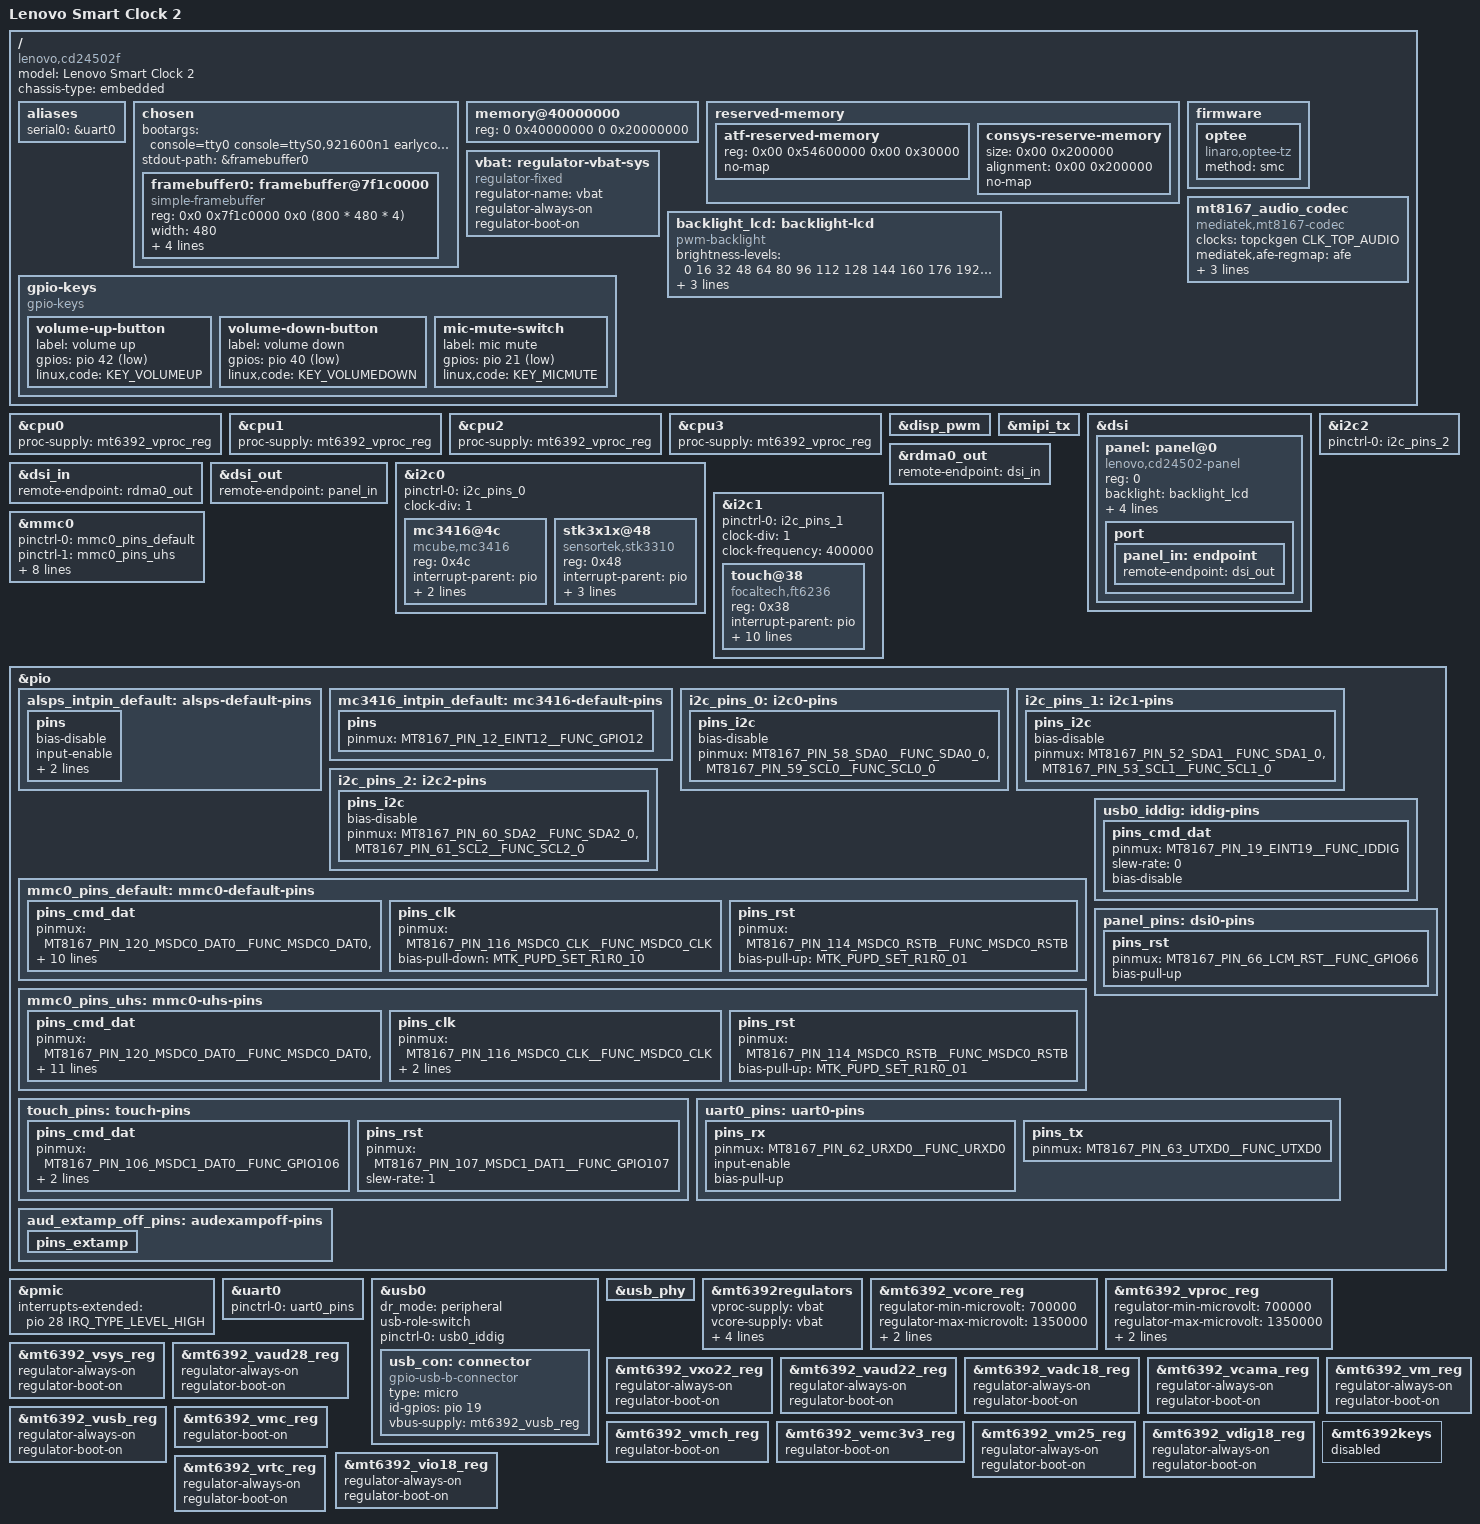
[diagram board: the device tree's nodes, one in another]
// SPDX-License-Identifier: GPL-2.0
/*
 * Copyright (c) 2025 FIXME
 */
/dts-v1/;
#include <dt-bindings/gpio/gpio.h>
#include <dt-bindings/input/linux-event-codes.h>
#include "mt8167.dtsi"
#include "mt6392.dtsi"

/ {
	model = "Lenovo Smart Clock 2";
	chassis-type = "embedded";
	compatible = "lenovo,cd24502f", "mediatek,mt8167";

	aliases {
		serial0 = &uart0;
	};

	chosen {
		#address-cells = <2>;
		#size-cells = <2>;
		bootargs = "console=tty0 console=ttyS0,921600n1 earlycon=uart8250,mmio32,0x11005000 fbcon=rotate:1";
		ranges;

		stdout-path = &framebuffer0;

		framebuffer0: framebuffer@7f1c0000 {
			compatible = "simple-framebuffer";
			reg = <0x0 0x7f1c0000 0x0 (800 * 480 * 4)>;
			width = <480>;
			height = <800>;
			stride = <(480 * 4)>;
			format = "a8r8g8b8";
			display = <&dsi>;
		};
	};

	memory@40000000 {
		device_type = "memory";
		reg = <0 0x40000000 0 0x20000000>;
	};

	reserved-memory {
		#address-cells = <2>;
		#size-cells = <2>;
		ranges;

		atf-reserved-memory {
			reg = <0x00 0x54600000 0x00 0x30000>;
			no-map;
		};

		consys-reserve-memory {
			size = <0x00 0x200000>;
			alignment = <0x00 0x200000>;
			no-map;
		};
	};

	firmware {
		optee {
			compatible = "linaro,optee-tz";
			method = "smc";
		};
	};

	vbat: regulator-vbat-sys {
		compatible = "regulator-fixed";
		regulator-name = "vbat";
		regulator-always-on;
		regulator-boot-on;
	};

	backlight_lcd: backlight-lcd {
		compatible = "pwm-backlight";
		brightness-levels = <
			  0  16  32  48  64  80  96 112
			128 144 160 176 192 208 224 240
			255
		>;
		default-brightness-level = <9>;
		power-supply = <&mt6392_vmch_reg>;
		pwms = <&disp_pwm 0 1000000>;
	};

	mt8167_audio_codec: mt8167_audio_codec {
		compatible = "mediatek,mt8167-codec";
		clocks = <&topckgen CLK_TOP_AUDIO>;
		clock-names = "bus";
		mediatek,afe-regmap = <&afe>;
		mediatek,apmixedsys-regmap = <&apmixedsys>;
		mediatek,dmic-wire-mode = <1>; /* 0(ONE_WIRE) 1(TWO_WIRE) */
		mediatek,headphone-cap-sel = <1>; /* 0(10UF) 1(22UF) 2(33UF) 3(47UF) */
	};
/*
	sound {
		compatible = "mediatek,mt8167s-es7243";
		mediatek,platform = <&afe>;
		pinctrl-0 = <&aud_default_pins>;
		pinctrl-1 = <&aud_extamp_on_pins>;
		pinctrl-2 = <&aud_extamp_off_pins>;
		pinctrl-names = "default", "extamp_on", "extamp_off";
		tdmadc-3p3v-supply = <&mt6392_vmch_reg>;
		tdmadc-1p8v-supply = <&mt6392_vcamio_reg>;
	};
*/
	gpio-keys {
		compatible = "gpio-keys";

		volume-up-button {
			label = "volume up";
			gpios = <&pio 42 GPIO_ACTIVE_LOW>;
			linux,code = <KEY_VOLUMEUP>;
		};

		volume-down-button {
			label = "volume down";
			gpios = <&pio 40 GPIO_ACTIVE_LOW>;
			linux,code = <KEY_VOLUMEDOWN>;
		};

		mic-mute-switch {
			label = "mic mute";
			gpios = <&pio 21 GPIO_ACTIVE_LOW>;
			linux,code = <KEY_MICMUTE>;
		};
	};
};

/* With the firmware on Android devices, cores don't seem to come back after out
   idle/unplug (though initial SMP boot is fine) */

&cpu0 {
	/delete-property/ cpu-idle-states;
	proc-supply = <&mt6392_vproc_reg>;
};

&cpu1 {
	/delete-property/ cpu-idle-states;
	proc-supply = <&mt6392_vproc_reg>;
};

&cpu2 {
	/delete-property/ cpu-idle-states;
	proc-supply = <&mt6392_vproc_reg>;
};

&cpu3 {
	/delete-property/ cpu-idle-states;
	proc-supply = <&mt6392_vproc_reg>;
};

/*
&cluster0_opp {
	opp-1500000000 {
		opp-hz = /bits/ 64 <1500000000>;
		opp-microvolt = <1300000>;
	};
};
*/
&disp_pwm {
	status = "okay";
};

&mipi_tx {
	status = "okay";
};

&dsi {
	status = "okay";

	panel: panel@0 {
		compatible = "lenovo,cd24502-panel";
		reg = <0>;
		backlight = <&backlight_lcd>;
		reset-gpios = <&pio 66 GPIO_ACTIVE_LOW>;
		rotation = <90>;
		power-supply = <&mt6392_vgp1_reg>;

		pinctrl-names = "default";
		pinctrl-0 = <&panel_pins>;

		port {
			panel_in: endpoint {
				remote-endpoint = <&dsi_out>;
			};
		};
	};
};

&rdma0_out {
	remote-endpoint = <&dsi_in>;
};

&dsi_in {
	remote-endpoint = <&rdma0_out>;
};

&dsi_out {
	remote-endpoint = <&panel_in>;
};

&i2c0 {
	pinctrl-names = "default";
	pinctrl-0 = <&i2c_pins_0>;
	clock-div = <1>;
	status = "okay";

	/* Accelerometer is mCube MC3416 */
	mc3416@4c {
		reg = <0x4c>;
		compatible = "mcube,mc3416";
		interrupt-parent = <&pio>;
		interrupts = <12 IRQ_TYPE_LEVEL_LOW>;
		pinctrl-names = "default";
		pinctrl-0 = <&mc3416_intpin_default>;
	};

	/* ALS/PS is Sensortek STK3310 */
	stk3x1x@48 {
		reg = <0x48>;
		compatible = "sensortek,stk3310";
		interrupt-parent = <&pio>;
		interrupts = <5 IRQ_TYPE_LEVEL_LOW>;
		proximity-near-level = <25>;
		pinctrl-names = "default";
		pinctrl-0 = <&alsps_intpin_default>;
	};
};

&i2c1 {
	pinctrl-names = "default";
	pinctrl-0 = <&i2c_pins_1>;
	status = "okay";
	clock-div = <1>;
	clock-frequency = <400000>;

	/* Touch is "EP0110M09" (FocalTech FT6336U?) */
	touch@38 {
		reg = <0x38>;
		compatible = "focaltech,ft6236";
		interrupt-parent = <&pio>;
		interrupts = <106 IRQ_TYPE_EDGE_FALLING>;
		reset-gpios = <&pio 107 GPIO_ACTIVE_LOW>;

		vcc-supply = <&mt6392_vio28_reg>;
		iovcc-supply = <&mt6392_vgp1_reg>;

		panel = <&panel>;
		touchscreen-size-x = <480>;
		touchscreen-size-y = <800>;
		//touchscreen-inverted-y;
		touchscreen-swapped-x-y;

		wakeup-source;

		pinctrl-names = "default";
		pinctrl-0 = <&touch_pins>;
	};
};

&i2c2 {
	pinctrl-names = "default";
	pinctrl-0 = <&i2c_pins_2>;
	status = "okay";
/*
	tas5805m: tas5805m@2d {
		compatible = "ti,tas5805m";
		pinctrl-names = "default";
		pinctrl-0 = <&spk_pin_default>;
		reg = <0x2d>;
		power_gpio = <&pio 69 0>;
		fault_gpio = <&pio 70 0>;
	};

	ad82128: ad82128@31 {
		compatible = "ESMT,ad82128";
		pinctrl-names = "default";
		pinctrl-0 = <&spk_pin_default>;
		reg = <0x31>;
		power_gpio = <&pio 69 0>;
		fault_gpio = <&pio 70 0>;
	};
		
	clock2@1d {
		reg = <0x1d>;
		compatible = "Tonly,clock2";

		interrupt-parent = <&pio>;
		interrupts = <18 IRQ_TYPE_EDGE_FALLING>;

	};*/
};

&mmc0 {
	status = "okay";

	pinctrl-names = "default", "state_uhs";
	pinctrl-0 = <&mmc0_pins_default>;
	pinctrl-1 = <&mmc0_pins_uhs>;

	bus-width = <8>;
	max-frequency = <200000000>;
	cap-mmc-highspeed;
	mmc-hs200-1_8v;
	cap-mmc-hw-reset;
	non-removable;

	vmmc-supply = <&mt6392_vemc3v3_reg>;
	vqmmc-supply = <&mt6392_vio18_reg>;
};

&pio {
	alsps_intpin_default: alsps-default-pins {
		pins {
			bias-disable;
			input-enable;
			slew-rate = <0>;
			pinmux = <MT8167_PIN_5_EINT5__FUNC_GPIO5>;
		};
	};

	mc3416_intpin_default: mc3416-default-pins {
		pins {
			pinmux = <MT8167_PIN_12_EINT12__FUNC_GPIO12>;
		};
	};

	i2c_pins_0: i2c0-pins {
		pins_i2c {
			bias-disable;
			pinmux = <MT8167_PIN_58_SDA0__FUNC_SDA0_0>,
				 <MT8167_PIN_59_SCL0__FUNC_SCL0_0>;
		};
	};

	i2c_pins_1: i2c1-pins {
		pins_i2c {
			bias-disable;
			pinmux = <MT8167_PIN_52_SDA1__FUNC_SDA1_0>,
				 <MT8167_PIN_53_SCL1__FUNC_SCL1_0>;
		};
	};

	i2c_pins_2: i2c2-pins {
		pins_i2c {
			bias-disable;
			pinmux = <MT8167_PIN_60_SDA2__FUNC_SDA2_0>,
				 <MT8167_PIN_61_SCL2__FUNC_SCL2_0>;
		};
	};
	
	mmc0_pins_default: mmc0-default-pins {
		pins_cmd_dat {
			pinmux = <MT8167_PIN_120_MSDC0_DAT0__FUNC_MSDC0_DAT0>,
				 <MT8167_PIN_119_MSDC0_DAT1__FUNC_MSDC0_DAT1>,
				 <MT8167_PIN_118_MSDC0_DAT2__FUNC_MSDC0_DAT2>,
				 <MT8167_PIN_117_MSDC0_DAT3__FUNC_MSDC0_DAT3>,
				 <MT8167_PIN_113_MSDC0_DAT4__FUNC_MSDC0_DAT4>,
				 <MT8167_PIN_112_MSDC0_DAT5__FUNC_MSDC0_DAT5>,
				 <MT8167_PIN_111_MSDC0_DAT6__FUNC_MSDC0_DAT6>,
				 <MT8167_PIN_110_MSDC0_DAT7__FUNC_MSDC0_DAT7>,
				 <MT8167_PIN_115_MSDC0_CMD__FUNC_MSDC0_CMD>;
			input-enable;
			bias-pull-up = <MTK_PUPD_SET_R1R0_01>;
		};

		pins_clk {
			pinmux = <MT8167_PIN_116_MSDC0_CLK__FUNC_MSDC0_CLK>;
			bias-pull-down = <MTK_PUPD_SET_R1R0_10>;
		};

		pins_rst {
			pinmux = <MT8167_PIN_114_MSDC0_RSTB__FUNC_MSDC0_RSTB>;
			bias-pull-up = <MTK_PUPD_SET_R1R0_01>;
		};
	};

	mmc0_pins_uhs: mmc0-uhs-pins {
		pins_cmd_dat {
			pinmux = <MT8167_PIN_120_MSDC0_DAT0__FUNC_MSDC0_DAT0>,
				 <MT8167_PIN_119_MSDC0_DAT1__FUNC_MSDC0_DAT1>,
				 <MT8167_PIN_118_MSDC0_DAT2__FUNC_MSDC0_DAT2>,
				 <MT8167_PIN_117_MSDC0_DAT3__FUNC_MSDC0_DAT3>,
				 <MT8167_PIN_113_MSDC0_DAT4__FUNC_MSDC0_DAT4>,
				 <MT8167_PIN_112_MSDC0_DAT5__FUNC_MSDC0_DAT5>,
				 <MT8167_PIN_111_MSDC0_DAT6__FUNC_MSDC0_DAT6>,
				 <MT8167_PIN_110_MSDC0_DAT7__FUNC_MSDC0_DAT7>,
				 <MT8167_PIN_115_MSDC0_CMD__FUNC_MSDC0_CMD>;
			input-enable;
			drive-strength = <MTK_DRIVE_6mA>;
			bias-pull-up = <MTK_PUPD_SET_R1R0_01>;
		};

		pins_clk {
			pinmux = <MT8167_PIN_116_MSDC0_CLK__FUNC_MSDC0_CLK>;
			drive-strength = <MTK_DRIVE_8mA>;
			bias-pull-down = <MTK_PUPD_SET_R1R0_10>;
		};

		pins_rst {
			pinmux = <MT8167_PIN_114_MSDC0_RSTB__FUNC_MSDC0_RSTB>;
			bias-pull-up = <MTK_PUPD_SET_R1R0_01>;
		};
	};
/*
	drvvbus_default: drvvbus-default-pins {
		pins_cmd_dat {
			pinmux = <MT8167_PIN_6_EINT6__FUNC_GPIO6>;
			output-low;
		};
	};

	usb_switch_default: usb-switch-pins {
		pins_cmd_dat {
			pinmux = <MT8167_PIN_12_EINT12__FUNC_PWM_A>;
			output-low;
		};
	};
*/
	usb0_iddig: iddig-pins {
		pins_cmd_dat {
			pinmux = <MT8167_PIN_19_EINT19__FUNC_IDDIG>;
			slew-rate = <0>;
			bias-disable;
		};
	};

	panel_pins: dsi0-pins {
		pins_rst {
			pinmux = <MT8167_PIN_66_LCM_RST__FUNC_GPIO66>;
			bias-pull-up;
		};
	};

	touch_pins: touch-pins {
		pins_cmd_dat {
			pinmux = <MT8167_PIN_106_MSDC1_DAT0__FUNC_GPIO106>;
			input-enable;
			bias-disable;
		};

		pins_rst {
			pinmux = <MT8167_PIN_107_MSDC1_DAT1__FUNC_GPIO107>;
			slew-rate = <1>;
		};
	};

	uart0_pins: uart0-pins {
		pins_rx {
			pinmux = <MT8167_PIN_62_URXD0__FUNC_URXD0>;
			input-enable;
			bias-pull-up;
		};
		pins_tx {
			pinmux = <MT8167_PIN_63_UTXD0__FUNC_UTXD0>;
		};
	};

	aud_extamp_off_pins: audexampoff-pins {
		pins_extamp {
			/*output-low;
			slew-rate = <1>;
			pinmux = <MT8167_PIN_51_SPI_MO__FUNC_GPIO51>;*/
		};
	};
/*
	aud_extamp_on_pins: audexampon-pins {
		pins_extamp {
			output-high;
			slew-rate = <1>;
			pinmux = <MT8167_PIN_51_SPI_MO__FUNC_GPIO51>;
		};
	};

	aud_default_pins: audiodefault-pins {
		pins_extamp {
			output-low;
			slew-rate = <1>;
			pinmux = <MT8167_PIN_51_SPI_MO__FUNC_GPIO51>;
		};

		pins_cmd_dat {
			drive-strength = <MTK_DRIVE_4mA>;
			pinmux = <MT8167_PIN_71_MSDC2_DAT1__FUNC_I2S_8CH_DO1
				  MT8167_PIN_72_MSDC2_DAT2__FUNC_I2S_8CH_LRCK
				  MT8167_PIN_73_MSDC2_DAT3__FUNC_I2S_8CH_BCK
				  MT8167_PIN_38_MRG_DI__FUNC_I2S0_DI>;
		};
	};*/
};

&pmic {
	interrupts-extended = <&pio 28 IRQ_TYPE_LEVEL_HIGH>;
};

&uart0 {
	status = "okay";

	pinctrl-names = "default";
	pinctrl-0 = <&uart0_pins>;
};

&usb0 {
	status = "okay";
	dr_mode = "peripheral";
	usb-role-switch;

	pinctrl-names = "default";
	pinctrl-0 = <&usb0_iddig>;

	//vusb33-supply = <&mt6392_vusb_reg>;

	usb_con: connector {
		compatible = "gpio-usb-b-connector", "usb-b-connector";
		type = "micro";
		id-gpios = <&pio 19 GPIO_OPEN_SOURCE>;
		vbus-supply = <&mt6392_vusb_reg>;
	};
};

&usb_phy {
	status = "okay";
};

&mt6392regulators {
	vproc-supply = <&vbat>;
	vcore-supply = <&vbat>;
	vsys-supply = <&vbat>;
	ldo1-supply = <&vbat>;
	ldo2-supply = <&vbat>;
	ldo3-supply = <&vbat>;
};

&mt6392_vcore_reg {
	regulator-min-microvolt = <700000>;
	regulator-max-microvolt = <1350000>;
	regulator-always-on;
	regulator-boot-on;
};

&mt6392_vproc_reg {
	regulator-min-microvolt = <700000>;
	regulator-max-microvolt = <1350000>;
	regulator-always-on;
	regulator-boot-on;
};

&mt6392_vsys_reg {
	regulator-always-on;
	regulator-boot-on;
};

&mt6392_vaud28_reg {
	regulator-always-on;
	regulator-boot-on;
};

&mt6392_vxo22_reg {
	regulator-always-on;
	regulator-boot-on;
};

&mt6392_vaud22_reg {
	regulator-always-on;
	regulator-boot-on;
};

&mt6392_vadc18_reg {
	regulator-always-on;
	regulator-boot-on;
};

&mt6392_vcama_reg {
	regulator-always-on;
	regulator-boot-on;
};

&mt6392_vusb_reg {
	regulator-always-on;
	regulator-boot-on;
};

&mt6392_vmc_reg {
	regulator-boot-on;
};

&mt6392_vmch_reg {
	regulator-boot-on;
};

&mt6392_vemc3v3_reg {
	regulator-boot-on;
};

&mt6392_vm25_reg {
	regulator-always-on;
	regulator-boot-on;
};

&mt6392_vdig18_reg {
	regulator-always-on;
	regulator-boot-on;
};

&mt6392_vm_reg {
	regulator-always-on;
	regulator-boot-on;
};

&mt6392_vio18_reg {
	regulator-always-on;
	regulator-boot-on;
};

&mt6392_vrtc_reg {
	regulator-always-on;
	regulator-boot-on;
};
/*
&btcvsd_snd {
	status = "okay";
};

&mt6392_audio_codec {
	status = "okay";
};*/

&mt6392keys {
	status = "disabled";
};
